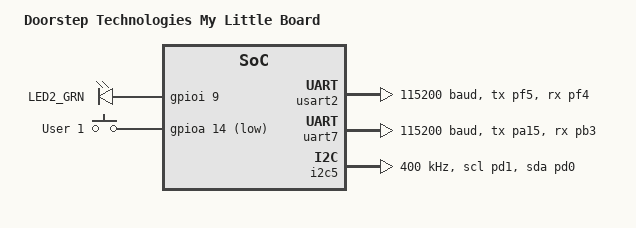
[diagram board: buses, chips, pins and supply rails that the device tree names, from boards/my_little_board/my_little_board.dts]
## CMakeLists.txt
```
cmake_minimum_required(VERSION 3.20.0)

set(DTC_OVERLAY_FILE
    "${CMAKE_CURRENT_SOURCE_DIR}/boards/osd32mp1_brk.overlay"
    "${CMAKE_CURRENT_SOURCE_DIR}/app.overlay"
)

# This will allow west to find the board named my_little_board
list(APPEND BOARD_ROOT ${CMAKE_CURRENT_SOURCE_DIR})
# Repo-root bindings: dts/bindings/doorstep,somedriver.yaml (fixes DT_HAS_* Kconfig symbols)
list(APPEND DTS_ROOT ${CMAKE_CURRENT_SOURCE_DIR}/..)

find_package(Zephyr REQUIRED)
project(my_zephyr_app)

zephyr_include_directories(include)

#
# Code for each target app depends on the homework requirements. Select only one.
#
target_sources(app PRIVATE
#	src/main.cpp
#   src/hello_world.c
    src/driver_demo.cpp
)

add_subdirectory(drivers/doorstep_somedriver)
```

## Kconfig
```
# SPDX-License-Identifier: Apache-2.0

mainmenu "Zephyr Application Configuration"

menuconfig APP_LED_SUBSYSTEM
	bool "LED Subsystem"
	default n
	help
	  Enable application LED features (blink timing, advanced options).

if APP_LED_SUBSYSTEM

config APP_HEARTBEAT_PERIOD_MS
	int "LED heartbeat period time (100-2000ms)"
	range 100 2000
	default 500
	help
	  Heartbeat period time in milliseconds.

choice APP_LED_BLINK_SLEEP_TIME
	prompt "LED blink sleep time"
	default APP_LED_BLINK_SLEEP_1S
	help
	  Time between LED state toggles while blinking.

config APP_LED_BLINK_SLEEP_250MS
	bool "250 ms (very fast)"

config APP_LED_BLINK_SLEEP_500MS
	bool "500 ms (fast)"

config APP_LED_BLINK_SLEEP_1S
	bool "1 s (medium)"

config APP_LED_BLINK_SLEEP_2S
	bool "2 s (slow)"

endchoice

config APP_LED_BLINK_SLEEP_MS
	int
	default 250 if APP_LED_BLINK_SLEEP_250MS
	default 500 if APP_LED_BLINK_SLEEP_500MS
	default 1000 if APP_LED_BLINK_SLEEP_1S
	default 2000 if APP_LED_BLINK_SLEEP_2S

menuconfig APP_LED_ADVANCED
	bool "Advanced LED settings"
	help
	  PWM-style brightness, fade timing, and expert-only tuning.

if APP_LED_ADVANCED

config APP_LED_BRIGHTNESS
	int "LED brightness (0-100)"
	range 0 100
	default 100
	help
	  LED brightness as a percentage.

config APP_LED_FADE_MS
	int "LED fade duration (ms)"
	range 0 5000
	default 500
	help
	  Time to ramp brightness; 0 disables fading.

config APP_LED_EXPERT
	bool "Enable expert settings"
	help
	  When enabled, the Expert settings submenu is shown in menuconfig.

# Expert submenu visibility is gated by APP_LED_EXPERT (visible if below).
menu "Expert settings"
	visible if APP_LED_EXPERT

config APP_LED_DEBUG
	bool "Enable LED debugging"
	depends on APP_LED_EXPERT
	default n
	help
	  Extra runtime logging and diagnostics for LED code paths.

config APP_LED_CUSTOM_BLINK_PATTERN
	bool "Custom blink pattern"
	depends on APP_LED_EXPERT
	default n
	help
	  Application-defined encoding for a custom on/off blink sequence.

endmenu

endif # APP_LED_ADVANCED

endif # APP_LED_SUBSYSTEM

# Sources Kconfig.zephyr in the Zephyr root directory ($srctree).
source "Kconfig.zephyr"

source "${APPLICATION_SOURCE_DIR}/drivers/doorstep_somedriver/Kconfig"
```

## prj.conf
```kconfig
# Board defconfig already sets: GPIO, CONFIG_CONSOLE, CONFIG_RAM_CONSOLE,
# CONFIG_RAM_CONSOLE_BUFFER_SIZE=1024, CONFIG_UART_CONSOLE=n, SERIAL, etc.
# SOC selects CONFIG_OPENAMP_RSC_TABLE when RAM_CONSOLE (see stm32mp1x Kconfig).

CONFIG_STDOUT_CONSOLE=y
CONFIG_PRINTK=y
CONFIG_LOG=n
# For Lesson 6 and 7: Task 1: Use the sensor driver API (set to y to enable sensor API)
# For Lesson 6 and 7: Task 2: Use the custom extension API (set to n to enable custom extension API)
CONFIG_SENSOR=n
CONFIG_DOORSTEP_SOMEDRIVER=y
CONFIG_APP_LED_SUBSYSTEM=y
CONFIG_SHELL=y
CONFIG_SHELL_BACKEND_SERIAL=y
CONFIG_SHELL_CMDS=y
```

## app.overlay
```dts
/ {
    doorstep_somedriver0: doorstep_somedriver {
    compatible = "doorstep,somedriver";
    status = "okay";
    }  ;
};
```

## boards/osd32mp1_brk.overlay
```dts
/*
 * OSD32MP1-BRK: the board has a bi-color LED chip — bright green and super red.
 * See: https://www.we-online.com/components/products/datasheet/150066SV74000.pdf
 * The green LED is defined in the base board devicetree called green_led_2 (alias led0);
 * this overlay adds the red LED and its alias (led1).
 *
 * Shell serial backend uses UART7 via chosen zephyr,shell-uart.
 */
/ {
	chosen {
		zephyr,console = &uart7;
		zephyr,shell-uart = &uart7;
	};

	leds {
		red_led_2: led_2 {
			label = "LED2_RED";
			gpios = <&gpioi 8 GPIO_ACTIVE_HIGH>;
			status = "okay";
		};
	};

	aliases {
		led1 = &red_led_2;
	};
};
```

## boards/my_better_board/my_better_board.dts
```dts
/*
 * Copyright (c) 2024 Antmicro <www.antmicro.com>
 *
 * SPDX-License-Identifier: Apache-2.0
 */

/dts-v1/;
#include <oct/osd32mp15x.dtsi>
#include <zephyr/dt-bindings/input/input-event-codes.h>

/ {
	model = "Doorstep Technologies My Better Board";
	compatible = "doorstep,my-better-board", "oct,osd32mp1-brk";

	chosen {
		zephyr,flash = &retram;
		zephyr,sram = &mcusram;
	};

	leds {
		compatible = "gpio-leds";

		green_led_2: led_1 {
			label = "LED2_GRN";
			gpios = <&gpioi 9 GPIO_ACTIVE_HIGH>;
			status = "okay";
		};
	};

	gpio_keys {
		compatible = "gpio-keys";

		user_button: button {
			label = "User 1";
			gpios = <&gpioa 14 GPIO_ACTIVE_LOW>;
			zephyr,code = <INPUT_KEY_0>;
		};
	};

	aliases {
		led0 = &green_led_2;
		sw0 = &user_button;
	};
};

&usart2 {
	pinctrl-0 = <&usart2_tx_pf5 &usart2_rx_pf4>;
	pinctrl-names = "default";
	current-speed = <115200>;
	status = "okay";
};

/*
 * osd32mp1_brk.overlay (merged for this course) binds console + shell to UART7 — enable it here.
 */
&uart7 {
	pinctrl-0 = <&uart7_tx_pa15 &uart7_rx_pb3>;
	pinctrl-names = "default";
	current-speed = <115200>;
	status = "okay";
};

&uart7_tx_pa15 {
	bias-disable;
};

&uart7_rx_pb3 {
	bias-disable;
};

&usart2_tx_pf5 {
	bias-disable;
};

&usart2_rx_pf4 {
	bias-disable;
};
```

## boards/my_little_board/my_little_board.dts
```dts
/*
 * Copyright (c) 2024 Antmicro <www.antmicro.com>
 *
 * SPDX-License-Identifier: Apache-2.0
 */

/dts-v1/;
#include <oct/osd32mp15x.dtsi>
#include <zephyr/dt-bindings/input/input-event-codes.h>

/ {
	model = "Doorstep Technologies My Little Board";
	compatible = "doorstep,my-little-board", "oct,osd32mp1-brk";

	chosen {
		/*
		 * By default, Zephyr console and shell are assigned to
		 * remoteproc. To enable console and shell over UART, uncomment
		 * following lines and set the correct config in
		 * osd32mp1_brk_defconfig "Serial Port" section in Zephyr
		 * board documentation.
		 * zephyr,console = &usart2;
		 * zephyr,shell-uart = &usart2;
		 */
		zephyr,flash = &retram;
		zephyr,sram = &mcusram;
	};

	leds {
		compatible = "gpio-leds";

		green_led_2: led_1 {
			label = "LED2_GRN";
			gpios = <&gpioi 9 GPIO_ACTIVE_HIGH>;
			status = "okay";
		};
	};

	gpio_keys {
		compatible = "gpio-keys";

		user_button: button {
			label = "User 1";
			gpios = <&gpioa 14 GPIO_ACTIVE_LOW>;
			zephyr,code = <INPUT_KEY_0>;
		};
	};

	aliases {
		led0 = &green_led_2;
		sw0 = &user_button;
	};
};

/*
 * Causes compilation error with custom board
 * &clk_hse {
 * clock-frequency = <DT_FREQ_M(24)>;
 * status = "okay";
 * };
 */

&spi4_miso_pe13 {
	slew-rate = "very-high-speed";
};

&usart2 {
	pinctrl-0 = <&usart2_tx_pf5 &usart2_rx_pf4>;
	pinctrl-names = "default";
	current-speed = <115200>;
	status = "okay";
};

&uart7 {
	pinctrl-0 = <&uart7_tx_pa15 &uart7_rx_pb3>;
	pinctrl-names = "default";
	current-speed = <115200>;
	status = "okay";
};

&i2c5 {
	pinctrl-0 = <&i2c5_scl_pd1 &i2c5_sda_pd0>;
	pinctrl-names = "default";
	status = "okay";
	clock-frequency = <I2C_BITRATE_FAST>;
};

&uart7_tx_pa15 {
	bias-disable;
};

&uart7_rx_pb3 {
	bias-disable;
};

&usart2_tx_pf5 {
	bias-disable;
};

&usart2_rx_pf4 {
	bias-disable;
};
```

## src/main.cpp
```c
#include <stdio.h>

#include <zephyr/autoconf.h>
#include <zephyr/drivers/gpio.h>
#include <zephyr/kernel.h>
#include <zephyr/logging/log.h>

/*
 * Zephyr's LOG_INF backend doesn't output to ram_console/trace0.
 * Only printf() reaches /sys/kernel/debug/remoteproc/remoteproc0/trace0.
 * Use these macros to get LOG_INF-style output through printf.
 */
#define TRACE_ERR(fmt, ...) printf("[ERR] " fmt "\n", ##__VA_ARGS__)
#define TRACE_WRN(fmt, ...) printf("[WRN] " fmt "\n", ##__VA_ARGS__)
#define TRACE_INF(fmt, ...) printf("[INF] " fmt "\n", ##__VA_ARGS__)
#define TRACE_DBG(fmt, ...) printf("[DBG] " fmt "\n", ##__VA_ARGS__)

/* The devicetree node identifier for the "led0" and "led1" aliases. */
#define LED_NODE_0 DT_ALIAS(led0)
#define LED_NODE_1 DT_ALIAS(led1)

// The OSD32MP1 Breakout Board has two LEDs: Green and Red.
// The Green LED is connected to the GPIOI pin 9 and the Red LED is connected to the GPIOI pin 8.
// Green LED configuration:
static const struct gpio_dt_spec led_green = GPIO_DT_SPEC_GET(LED_NODE_0, gpios);
// Red LED configuration:
static const struct gpio_dt_spec led_red = GPIO_DT_SPEC_GET(LED_NODE_1, gpios);

// TODO: Uncomment this to enable Zephyr logging
// LOG_MODULE_REGISTER(main, LOG_LEVEL_INF);

int main(void)
{
    bool led_state = true;
    uint32_t count = 0;

    // Green LED check if the GPIO is ready
    if (!gpio_is_ready_dt(&led_green)) return 0;
    // Red LED check if the GPIO is ready
    if (!gpio_is_ready_dt(&led_red)) return 0;

    // Green LED configure the GPIO as output and active high
    if (gpio_pin_configure_dt(&led_green, GPIO_OUTPUT_ACTIVE) < 0) return 0;
    // Red LED configure the GPIO as output and active high
    if (gpio_pin_configure_dt(&led_red, GPIO_OUTPUT_ACTIVE) < 0) return 0;

    printk("LED application started - trace0 enabled\n");

    while (1) {
        // Green LED toggle the GPIO
        if (gpio_pin_toggle_dt(&led_green) < 0) return 0;

        led_state = !led_state;
        TRACE_INF("(%d) LED state: %s", ++count, led_state ? "ON" : "OFF");
        k_msleep(CONFIG_APP_HEARTBEAT_PERIOD_MS);

        // Red LED toggle the GPIO
        if (gpio_pin_toggle_dt(&led_red) < 0) return 0;
        k_msleep(CONFIG_APP_HEARTBEAT_PERIOD_MS);
    }
    return 0;
}
```

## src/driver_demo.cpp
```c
#include <stdio.h>

#include <limits.h>

#include <zephyr/autoconf.h>
#include <zephyr/device.h>
#include <zephyr/devicetree.h>
#include <zephyr/drivers/gpio.h>
#include <zephyr/kernel.h>

#if IS_ENABLED(CONFIG_DOORSTEP_SOMEDRIVER)
#if IS_ENABLED(CONFIG_SENSOR)
#include <zephyr/drivers/gpio.h>
#include <zephyr/drivers/sensor.h>
#else
#include <zephyr/drivers/doorstep.h>
#endif
#if IS_ENABLED(CONFIG_SHELL)
#include <zephyr/shell/shell.h>
#endif
#endif

/*
 * Zephyr's LOG_INF backend doesn't output to ram_console/trace0.
 * Only printf() reaches /sys/kernel/debug/remoteproc/remoteproc0/trace0.
 * Use these macros to get LOG_INF-style output through printf.
 */
#define TRACE_ERR(fmt, ...) printf("[ERR] " fmt "\n", ##__VA_ARGS__)
#define TRACE_WRN(fmt, ...) printf("[WRN] " fmt "\n", ##__VA_ARGS__)
#define TRACE_INF(fmt, ...) printf("[INF] " fmt "\n", ##__VA_ARGS__)
#define TRACE_DBG(fmt, ...) printf("[DBG] " fmt "\n", ##__VA_ARGS__)

/* The devicetree node identifier for the "led0" and "led1" aliases. */
#define LED_NODE_0 DT_ALIAS(led0)
#define LED_NODE_1 DT_ALIAS(led1)

// The OSD32MP1 Breakout Board has two LEDs: Green and Red.
// The Green LED is connected to the GPIOI pin 9 and the Red LED is connected to the GPIOI pin 8.
// Green LED configuration:
static const struct gpio_dt_spec led_green = GPIO_DT_SPEC_GET(LED_NODE_0, gpios);
// Red LED configuration:
static const struct gpio_dt_spec led_red = GPIO_DT_SPEC_GET(LED_NODE_1, gpios);

namespace {

// Lesson 6 and 7: Task 1: Use the sensor driver API
#if IS_ENABLED(CONFIG_SENSOR)

void call_driver_api_with_sensor_driver(void)
{
#if IS_ENABLED(CONFIG_DOORSTEP_SOMEDRIVER)
	TRACE_INF("doorstep_somedriver probe");
	const struct device *dev = DEVICE_DT_GET(DT_NODELABEL(doorstep_somedriver0));
	if (dev == NULL) {
		TRACE_ERR("Device not found");
		return;
	}

	// Fetch sensor value
	int ret = sensor_sample_fetch(dev);
	if (ret < 0) {
		TRACE_ERR("Failed to fetch sensor value");
		return;
	}
	TRACE_INF("Sensor driver: sensor_sample_fetch returned %d", ret);

	// Sleep for half a second to allow the LED to visually toggle
	k_msleep(500);

	// Get sensor value for all channels
	struct sensor_value val;
	ret = sensor_channel_get(dev, SENSOR_CHAN_ALL, &val);
	if (ret < 0) {
		TRACE_ERR("Failed to get sensor value");
		return;
	}
	TRACE_INF("Sensor driver: sensor_channel_get returned %d, %d", val.val1, val.val2);
#else
	TRACE_INF("sensor driver disabled in configuration");
#endif
}

#else

// Lesson 6 and 7: Task 2: Use the custom extension API
void call_driver_api_with_custom_extension(void)
{
#if IS_ENABLED(CONFIG_DOORSTEP_SOMEDRIVER)
	TRACE_INF("doorstep_somedriver probe");
	const struct device *dev = DEVICE_DT_GET(DT_NODELABEL(doorstep_somedriver0));
	if (dev == NULL) {
		TRACE_ERR("Device not found");
		return;
	}

	int foo = 1;
	int bar = 2;
	int ret = doorstep_do_this(dev, foo, bar);
	if (ret < 0) {
		TRACE_ERR("doorstep_do_this failed: %d", ret);
		return;
	}
	TRACE_INF("doorstep_do_this returned %d", ret);

	// Sleep for half a second to allow the LED to visually toggle
	k_msleep(500);

	void *baz = NULL;
	doorstep_do_that(dev, baz);
	TRACE_INF("doorstep_do_that finished");
#else
	TRACE_INF("doorstep_somedriver disabled in configuration");
#endif
}

#endif

} /* namespace */

#if IS_ENABLED(CONFIG_SHELL) && IS_ENABLED(CONFIG_SENSOR) && IS_ENABLED(CONFIG_DOORSTEP_SOMEDRIVER)

extern "C" {

static int cmd_sensor_fetch(const struct shell *sh, size_t argc, char **argv)
{
	ARG_UNUSED(argc);
	ARG_UNUSED(argv);

	const struct device *dev = DEVICE_DT_GET(DT_NODELABEL(doorstep_somedriver0));

	if (!device_is_ready(dev)) {
		shell_error(sh, "Sensor device not ready");
		return -ENODEV;
	}

	int ret = sensor_sample_fetch(dev);

	if (ret < 0) {
		shell_error(sh, "sensor_sample_fetch failed: %d", ret);
	} else {
		shell_print(sh, "sensor_sample_fetch: %d", ret);
	}

	return ret;
}

static int cmd_sensor_read(const struct shell *sh, size_t argc, char **argv)
{
	ARG_UNUSED(argc);
	ARG_UNUSED(argv);

	const struct device *dev = DEVICE_DT_GET(DT_NODELABEL(doorstep_somedriver0));

	if (!device_is_ready(dev)) {
		shell_error(sh, "Sensor device not ready");
		return -ENODEV;
	}

	struct sensor_value val;
	int ret = sensor_channel_get(dev, SENSOR_CHAN_ALL, &val);

	if (ret < 0) {
		shell_error(sh, "sensor_channel_get failed: %d", ret);
	} else {
		// TODO: val1 + val2*1e-6 is the Zephyr sensor_value decoding (integer part + micro fractional
		//       part); use sensor_value_to_float/double helpers in sensor.h instead of assuming a mantissa/exponent layout.
		shell_print(sh, "sensor_channel_get: ret=%d val1=%d val2=%d", ret, val.val1, val.val2);
	}

	return ret;
}

static int cmd_sensor_info(const struct shell *sh, size_t argc, char **argv)
{
	ARG_UNUSED(argc);
	ARG_UNUSED(argv);

	const struct device *dev = DEVICE_DT_GET(DT_NODELABEL(doorstep_somedriver0));

	shell_print(sh, "name: %s", dev->name);
	shell_print(sh, "ready: %s", device_is_ready(dev) ? "true" : "false");
	return 0;
}

} /* extern "C" */

SHELL_STATIC_SUBCMD_SET_CREATE(sub_sensor,
			     SHELL_CMD(fetch, NULL, "Fetch a new sensor sample", cmd_sensor_fetch),
			     SHELL_CMD(read, NULL, "Read sensor channel values", cmd_sensor_read),
			     SHELL_CMD(info, NULL, "Show sensor device name and ready state", cmd_sensor_info),
			     SHELL_SUBCMD_SET_END);

SHELL_CMD_REGISTER(sensor, &sub_sensor, "Sensor commands", NULL);

#endif

#if IS_ENABLED(CONFIG_SHELL) && !IS_ENABLED(CONFIG_SENSOR) && IS_ENABLED(CONFIG_DOORSTEP_SOMEDRIVER)

/* SHELL_CMD_ARG mandatory count includes the subcommand token: set + foo + bar */
#define SENSOR_SHELL_SET_ARGC 3

extern "C" {

/* Last parameters for sensor get; default to zero until sensor set. */
static int sensor_shell_foo = 0;
static int sensor_shell_bar = 0;

static int cmd_sensor_get(const struct shell *sh, size_t argc, char **argv)
{
	ARG_UNUSED(argc);
	ARG_UNUSED(argv);

	const struct device *dev = DEVICE_DT_GET(DT_NODELABEL(doorstep_somedriver0));

	if (!device_is_ready(dev)) {
		shell_error(sh, "Doorstep device not ready");
		return -ENODEV;
	}

	const int foo = sensor_shell_foo;
	const int bar = sensor_shell_bar;
	int ret = doorstep_do_this(dev, foo, bar);

	if (ret < 0) {
		shell_error(sh, "doorstep_do_this failed: %d", ret);
	} else {
		shell_print(sh, "doorstep_do_this(foo=%d, bar=%d): %d", foo, bar, ret);
	}

	return ret;
}

/* argv: [0]=set, [1]=foo, [2]=bar — argc fixed by SHELL_CMD_ARG(..., SENSOR_SHELL_SET_ARGC, 0). */
static int cmd_sensor_set(const struct shell *sh, size_t argc, char **argv)
{
	ARG_UNUSED(argc);

	int parse_err = 0;
	const long foo_l = shell_strtol(argv[1], 10, &parse_err);

	if (parse_err != 0) {
		shell_error(sh, "foo must be an integer");
		return parse_err;
	}

	parse_err = 0;
	const long bar_l = shell_strtol(argv[2], 10, &parse_err);

	if (parse_err != 0) {
		shell_error(sh, "bar must be an integer");
		return parse_err;
	}

	if (foo_l > INT_MAX || foo_l < INT_MIN || bar_l > INT_MAX || bar_l < INT_MIN) {
		shell_error(sh, "foo and bar must fit in int range");
		return -ERANGE;
	}

	const int foo = (int)foo_l;
	const int bar = (int)bar_l;

	sensor_shell_foo = foo;
	sensor_shell_bar = bar;

	shell_print(sh, "sensor set: success (foo=%d, bar=%d)", foo, bar);

	return 0;
}

} /* extern "C" */

SHELL_STATIC_SUBCMD_SET_CREATE(sub_sensor_doorstep,
			       SHELL_CMD(get, NULL, "Call doorstep_do_this with last foo/bar from sensor set", cmd_sensor_get),
			       SHELL_CMD_ARG(set, NULL, "Store integer foo and bar for sensor get", cmd_sensor_set,
					      SENSOR_SHELL_SET_ARGC, 0),
			       SHELL_SUBCMD_SET_END);

SHELL_CMD_REGISTER(sensor, &sub_sensor_doorstep, "Doorstep sensor commands", NULL);

#endif

int main(void)
{
	TRACE_INF("Main function started");
	TRACE_INF("Calling driver API");

// Lesson 6 and 7: Task 1: Use the sensor driver API
// Lesson 6 and 7: Task 2: Use the custom extension API
#if IS_ENABLED(CONFIG_SENSOR)
	call_driver_api_with_sensor_driver(); // Task 1
#else
	call_driver_api_with_custom_extension(); // Task 2
#endif
	TRACE_INF("Main function finished");
	return 0;
}
```
